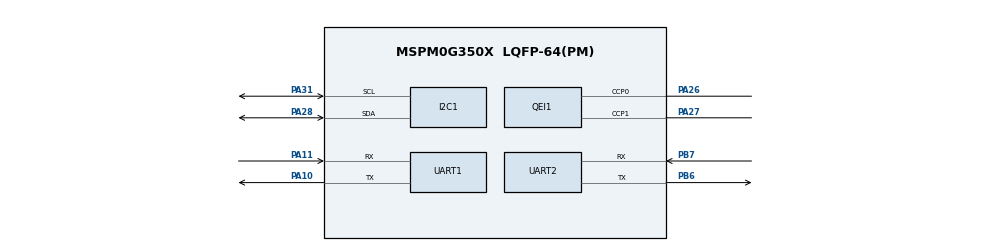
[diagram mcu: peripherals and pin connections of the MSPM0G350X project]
/**
 * @cliArgs --device "MSPM0G350X" --part "Default" --package "LQFP-64(PM)" --product "mspm0_sdk@2.11.00.07"
 * @versions {"tool":"1.26.2+4477"}
 */

/**
 * Import the modules used in this configuration.
 */
const GPIO   = scripting.addModule("/ti/driverlib/GPIO", {}, false);
const GPIO1  = GPIO.addInstance();
const GPIO2  = GPIO.addInstance();
const GPIO3  = GPIO.addInstance();
const GPIO4  = GPIO.addInstance();
const GPIO5  = GPIO.addInstance();
const I2C    = scripting.addModule("/ti/driverlib/I2C", {}, false);
const I2C1   = I2C.addInstance();
const PWM    = scripting.addModule("/ti/driverlib/PWM", {}, false);
const PWM1   = PWM.addInstance();
const QEI    = scripting.addModule("/ti/driverlib/QEI", {}, false);
const QEI1   = QEI.addInstance();
const SYSCTL = scripting.addModule("/ti/driverlib/SYSCTL");
const TIMER  = scripting.addModule("/ti/driverlib/TIMER", {}, false);
const TIMER1 = TIMER.addInstance();
const UART   = scripting.addModule("/ti/driverlib/UART", {}, false);
const UART1  = UART.addInstance();
const UART2  = UART.addInstance();

/**
 * Write custom configuration values to the imported modules.
 */
const gate7  = system.clockTree["MFCLKGATE"];
gate7.enable = true;

GPIO1.$name                         = "GPIO_TEST";
GPIO1.port                          = "PORTB";
GPIO1.associatedPins[0].$name       = "LED";
GPIO1.associatedPins[0].assignedPin = "22";

const Board = scripting.addModule("/ti/driverlib/Board", {}, false);

GPIO2.$name                         = "GRAY_SENSOR";
GPIO2.port                          = "PORTB";
GPIO2.associatedPins.create(8);
GPIO2.associatedPins[0].$name       = "S1";
GPIO2.associatedPins[0].direction   = "INPUT";
GPIO2.associatedPins[0].assignedPin = "5";
GPIO2.associatedPins[1].$name       = "S2";
GPIO2.associatedPins[1].direction   = "INPUT";
GPIO2.associatedPins[1].assignedPin = "15";
GPIO2.associatedPins[2].$name       = "S3";
GPIO2.associatedPins[2].direction   = "INPUT";
GPIO2.associatedPins[2].assignedPin = "16";
GPIO2.associatedPins[3].$name       = "S4";
GPIO2.associatedPins[3].assignedPin = "12";
GPIO2.associatedPins[3].direction   = "INPUT";
GPIO2.associatedPins[4].$name       = "S5";
GPIO2.associatedPins[4].direction   = "INPUT";
GPIO2.associatedPins[4].assignedPin = "13";
GPIO2.associatedPins[5].$name       = "S6";
GPIO2.associatedPins[5].direction   = "INPUT";
GPIO2.associatedPins[5].assignedPin = "23";
GPIO2.associatedPins[6].$name       = "S7";
GPIO2.associatedPins[6].assignedPin = "26";
GPIO2.associatedPins[6].direction   = "INPUT";
GPIO2.associatedPins[7].$name       = "S8";
GPIO2.associatedPins[7].direction   = "INPUT";
GPIO2.associatedPins[7].assignedPin = "27";

GPIO3.$name                          = "MOTOR_DIR";
GPIO3.associatedPins.create(4);
GPIO3.associatedPins[0].$name        = "AIN1";
GPIO3.associatedPins[0].assignedPort = "PORTB";
GPIO3.associatedPins[0].assignedPin  = "17";
GPIO3.associatedPins[1].$name        = "AIN2";
GPIO3.associatedPins[1].assignedPort = "PORTB";
GPIO3.associatedPins[1].assignedPin  = "19";
GPIO3.associatedPins[2].$name        = "BIN1";
GPIO3.associatedPins[2].assignedPort = "PORTA";
GPIO3.associatedPins[2].assignedPin  = "16";
GPIO3.associatedPins[3].$name        = "BIN2";
GPIO3.associatedPins[3].assignedPort = "PORTB";
GPIO3.associatedPins[3].assignedPin  = "24";

GPIO4.$name                         = "ENCODER_M1_SW";
GPIO4.port                          = "PORTA";
GPIO4.associatedPins.create(2);
GPIO4.associatedPins[0].$name       = "A";
GPIO4.associatedPins[0].direction   = "INPUT";
GPIO4.associatedPins[0].assignedPin = "25";
GPIO4.associatedPins[0].polarity    = "RISE_FALL";
GPIO4.associatedPins[0].interruptEn = true;
GPIO4.associatedPins[1].$name       = "B";
GPIO4.associatedPins[1].direction   = "INPUT";
GPIO4.associatedPins[1].assignedPin = "14";
GPIO4.associatedPins[1].polarity    = "RISE_FALL";
GPIO4.associatedPins[1].interruptEn = true;

GPIO5.$name                              = "START_BUTTON";
GPIO5.port                               = "PORTB";
GPIO5.associatedPins.create(3);
GPIO5.associatedPins[0].$name            = "REQUIREMENT2";
GPIO5.associatedPins[0].direction        = "INPUT";
GPIO5.associatedPins[0].internalResistor = "PULL_UP";
GPIO5.associatedPins[0].assignedPin      = "14";
GPIO5.associatedPins[1].$name            = "REQUIREMENT45";
GPIO5.associatedPins[1].direction        = "INPUT";
GPIO5.associatedPins[1].internalResistor = "PULL_UP";
GPIO5.associatedPins[1].assignedPin      = "11";
GPIO5.associatedPins[2].$name            = "REQUIREMENT6";
GPIO5.associatedPins[2].direction        = "INPUT";
GPIO5.associatedPins[2].internalResistor = "PULL_UP";
GPIO5.associatedPins[2].assignedPin      = "10";

I2C1.$name                             = "OLED_I2C";
I2C1.basicEnableController             = true;
I2C1.basicClockSource                  = "MFCLK";
I2C1.peripheral.$assign                = "I2C0";
I2C1.peripheral.sdaPin.$assign         = "PA28";
I2C1.peripheral.sclPin.$assign         = "PA31";
I2C1.sdaPinConfig.hideOutputInversion  = scripting.forceWrite(false);
I2C1.sdaPinConfig.onlyInternalResistor = scripting.forceWrite(false);
I2C1.sdaPinConfig.passedPeripheralType = scripting.forceWrite("Digital");
I2C1.sdaPinConfig.$name                = "ti_driverlib_gpio_GPIOPinGeneric6";
I2C1.sclPinConfig.hideOutputInversion  = scripting.forceWrite(false);
I2C1.sclPinConfig.onlyInternalResistor = scripting.forceWrite(false);
I2C1.sclPinConfig.passedPeripheralType = scripting.forceWrite("Digital");
I2C1.sclPinConfig.$name                = "ti_driverlib_gpio_GPIOPinGeneric7";

PWM1.$name                              = "MOTOR_PWM";
PWM1.timerCount                         = 1600;
PWM1.pwmMode                            = "EDGE_ALIGN_UP";
PWM1.peripheral.$assign                 = "TIMG0";
PWM1.PWM_CHANNEL_0.$name                = "ti_driverlib_pwm_PWMTimerCC0";
PWM1.PWM_CHANNEL_1.$name                = "ti_driverlib_pwm_PWMTimerCC1";
PWM1.ccp0PinConfig.$name                = "ti_driverlib_gpio_GPIOPinGeneric2";
PWM1.ccp0PinConfig.direction            = scripting.forceWrite("OUTPUT");
PWM1.ccp0PinConfig.hideOutputInversion  = scripting.forceWrite(false);
PWM1.ccp0PinConfig.onlyInternalResistor = scripting.forceWrite(false);
PWM1.ccp0PinConfig.passedPeripheralType = scripting.forceWrite("Digital");
PWM1.ccp1PinConfig.$name                = "ti_driverlib_gpio_GPIOPinGeneric3";
PWM1.ccp1PinConfig.direction            = scripting.forceWrite("OUTPUT");
PWM1.ccp1PinConfig.hideOutputInversion  = scripting.forceWrite(false);
PWM1.ccp1PinConfig.onlyInternalResistor = scripting.forceWrite(false);
PWM1.ccp1PinConfig.passedPeripheralType = scripting.forceWrite("Digital");

QEI1.$name                              = "ENCODER_M2";
QEI1.peripheral.$assign                 = "TIMG8";
QEI1.peripheral.ccp0Pin.$assign         = "PA26";
QEI1.peripheral.ccp1Pin.$assign         = "PA27";
QEI1.ccp0PinConfig.$name                = "ti_driverlib_gpio_GPIOPinGeneric4";
QEI1.ccp0PinConfig.hideOutputInversion  = scripting.forceWrite(false);
QEI1.ccp0PinConfig.onlyInternalResistor = scripting.forceWrite(false);
QEI1.ccp0PinConfig.passedPeripheralType = scripting.forceWrite("Digital");
QEI1.ccp1PinConfig.$name                = "ti_driverlib_gpio_GPIOPinGeneric5";
QEI1.ccp1PinConfig.hideOutputInversion  = scripting.forceWrite(false);
QEI1.ccp1PinConfig.onlyInternalResistor = scripting.forceWrite(false);
QEI1.ccp1PinConfig.passedPeripheralType = scripting.forceWrite("Digital");

SYSCTL.forceDefaultClkConfig = true;
SYSCTL.clockTreeEn           = true;

TIMER1.$name              = "TIMER_1MS";
TIMER1.timerMode          = "PERIODIC";
TIMER1.interrupts         = ["ZERO"];
TIMER1.timerPeriod        = "1 ms";
TIMER1.peripheral.$assign = "TIMG7";

UART1.$name                    = "UART_0";
UART1.targetBaudRate           = 115200;
UART1.enabledInterrupts        = ["RX"];
UART1.peripheral.rxPin.$assign = "PA11";
UART1.peripheral.txPin.$assign = "PA10";
UART1.txPinConfig.$name        = "ti_driverlib_gpio_GPIOPinGeneric0";
UART1.rxPinConfig.$name        = "ti_driverlib_gpio_GPIOPinGeneric1";

UART2.$name                    = "UART_1";
UART2.targetBaudRate           = 115200;
UART2.peripheral.$assign       = "UART1";
UART2.peripheral.rxPin.$assign = "PB7";
UART2.peripheral.txPin.$assign = "PB6";
UART2.txPinConfig.$name        = "ti_driverlib_gpio_GPIOPinGeneric8";
UART2.rxPinConfig.$name        = "ti_driverlib_gpio_GPIOPinGeneric9";

/**
 * Pinmux solution for unlocked pins/peripherals. This ensures that minor changes to the automatic solver in a future
 * version of the tool will not impact the pinmux you originally saw.  These lines can be completely deleted in order to
 * re-solve from scratch.
 */
GPIO1.associatedPins[0].pin.$suggestSolution = "PB22";
Board.peripheral.$suggestSolution            = "DEBUGSS";
Board.peripheral.swclkPin.$suggestSolution   = "PA20";
Board.peripheral.swdioPin.$suggestSolution   = "PA19";
GPIO2.associatedPins[0].pin.$suggestSolution = "PB5";
GPIO2.associatedPins[1].pin.$suggestSolution = "PB15";
GPIO2.associatedPins[2].pin.$suggestSolution = "PB16";
GPIO2.associatedPins[3].pin.$suggestSolution = "PB12";
GPIO2.associatedPins[4].pin.$suggestSolution = "PB13";
GPIO2.associatedPins[5].pin.$suggestSolution = "PB23";
GPIO2.associatedPins[6].pin.$suggestSolution = "PB26";
GPIO2.associatedPins[7].pin.$suggestSolution = "PB27";
GPIO3.associatedPins[0].pin.$suggestSolution = "PB17";
GPIO3.associatedPins[1].pin.$suggestSolution = "PB19";
GPIO3.associatedPins[2].pin.$suggestSolution = "PA16";
GPIO3.associatedPins[3].pin.$suggestSolution = "PB24";
GPIO4.associatedPins[0].pin.$suggestSolution = "PA25";
GPIO4.associatedPins[1].pin.$suggestSolution = "PA14";
GPIO5.associatedPins[0].pin.$suggestSolution = "PB14";
GPIO5.associatedPins[1].pin.$suggestSolution = "PB11";
GPIO5.associatedPins[2].pin.$suggestSolution = "PB10";
PWM1.peripheral.ccp0Pin.$suggestSolution     = "PA12";
PWM1.peripheral.ccp1Pin.$suggestSolution     = "PA13";
UART1.peripheral.$suggestSolution            = "UART0";
